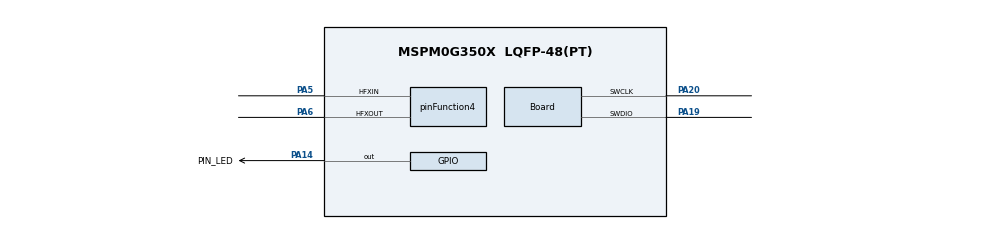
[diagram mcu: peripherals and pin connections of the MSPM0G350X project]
/**
 * @cliArgs --device "MSPM0G350X" --package "LQFP-48(PT)" --part "Default" --product "mspm0_sdk@2.01.00.03"
 * @versions {"tool":"1.20.0+3587"}
 */

/**
 * Import the modules used in this configuration.
 */
const GPIO          = scripting.addModule("/ti/driverlib/GPIO", {}, false);
const GPIO1         = GPIO.addInstance();
const SYSCTL        = scripting.addModule("/ti/driverlib/SYSCTL");
const ProjectConfig = scripting.addModule("/ti/project_config/ProjectConfig");

/**
 * Write custom configuration values to the imported modules.
 */
const divider9       = system.clockTree["UDIV"];
divider9.divideValue = 2;

const multiplier2         = system.clockTree["PLL_QDIV"];
multiplier2.multiplyValue = 4;

const mux4       = system.clockTree["EXHFMUX"];
mux4.inputSelect = "EXHFMUX_XTAL";

const mux8       = system.clockTree["HSCLKMUX"];
mux8.inputSelect = "HSCLKMUX_SYSPLL0";

const mux12       = system.clockTree["SYSPLLMUX"];
mux12.inputSelect = "zSYSPLLMUX_HFCLK";

const pinFunction4                        = system.clockTree["HFXT"];
pinFunction4.enable                       = true;
pinFunction4.inputFreq                    = 40;
pinFunction4.peripheral.$assign           = "SYSCTL";
pinFunction4.peripheral.hfxInPin.$assign  = "PA5";
pinFunction4.peripheral.hfxOutPin.$assign = "PA6";

GPIO1.$name                         = "GPIO_LED";
GPIO1.port                          = "PORTA";
GPIO1.associatedPins[0].$name       = "PIN_LED";
GPIO1.associatedPins[0].assignedPin = "14";
GPIO1.associatedPins[0].pin.$assign = "PA14";

const Board                       = scripting.addModule("/ti/driverlib/Board", {}, false);
Board.peripheral.$assign          = "DEBUGSS";
Board.peripheral.swclkPin.$assign = "PA20";
Board.peripheral.swdioPin.$assign = "PA19";

SYSCTL.forceDefaultClkConfig = true;
SYSCTL.clockTreeEn           = true;

ProjectConfig.deviceSpin = "MSPM0G3507";
